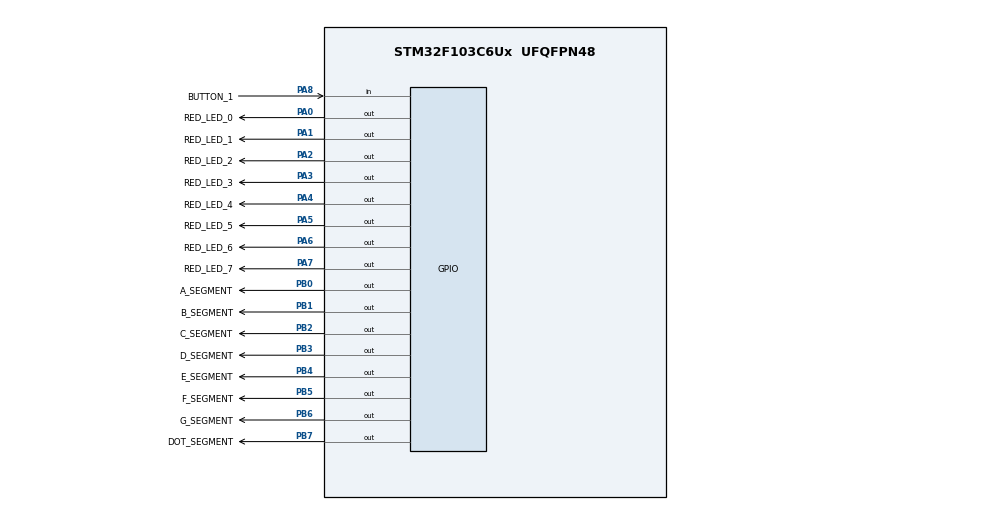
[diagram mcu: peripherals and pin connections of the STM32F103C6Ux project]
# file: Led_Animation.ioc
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Mcu.Family=STM32F1
Mcu.Name=STM32F103C6Ux
Mcu.Package=UFQFPN48
NVIC.PriorityGroup=NVIC_PRIORITYGROUP_4
NVIC.TIM2_IRQn=true\:0\:0\:false\:false\:true\:true\:true
PA0-WKUP.GPIO_Label=RED_LED_0
PA0-WKUP.Signal=GPIO_Output
PA1.GPIO_Label=RED_LED_1
PA1.Signal=GPIO_Output
PA2.GPIO_Label=RED_LED_2
PA2.Signal=GPIO_Output
PA3.GPIO_Label=RED_LED_3
PA3.Signal=GPIO_Output
PA4.GPIO_Label=RED_LED_4
PA4.Signal=GPIO_Output
PA5.GPIO_Label=RED_LED_5
PA5.Signal=GPIO_Output
PA6.GPIO_Label=RED_LED_6
PA6.Signal=GPIO_Output
PA7.GPIO_Label=RED_LED_7
PA7.Signal=GPIO_Output
PA8.GPIO_Label=BUTTON_1
PA8.Signal=GPIO_Input
PB0.GPIO_Label=A_SEGMENT
PB0.Signal=GPIO_Output
PB1.GPIO_Label=B_SEGMENT
PB1.Signal=GPIO_Output
PB2.GPIO_Label=C_SEGMENT
PB2.Signal=GPIO_Output
PB3.GPIO_Label=D_SEGMENT
PB3.Signal=GPIO_Output
PB4.GPIO_Label=E_SEGMENT
PB4.Signal=GPIO_Output
PB5.GPIO_Label=F_SEGMENT
PB5.Signal=GPIO_Output
PB6.GPIO_Label=G_SEGMENT
PB6.Signal=GPIO_Output
PB7.GPIO_Label=DOT_SEGMENT
PB7.Signal=GPIO_Output
ProjectManager.HeapSize=0x200
ProjectManager.StackSize=0x400
ProjectManager.TargetToolchain=STM32CubeIDE
RCC.APB1Freq_Value=8000000
RCC.APB2Freq_Value=8000000
TIM2.AutoReloadPreload=TIM_AUTORELOAD_PRELOAD_DISABLE
TIM2.Period=9
TIM2.Prescaler=7999
VP_SYS_VS_ND.Mode=No_Debug
VP_TIM2_VS_ClockSourceINT.Mode=Internal
VP_TIM3_VS_ClockSourceITR.Mode=TriggerSource_ITR3
board=custom

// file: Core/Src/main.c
/* USER CODE BEGIN Header */
/**
  ******************************************************************************
  * @file           : main.c
  * @brief          : Main program body
  ******************************************************************************
  * @attention
  *
  * <h2><center>&copy; Copyright (c) 2021 STMicroelectronics.
  * All rights reserved.</center></h2>
  *
  * This software component is licensed by ST under BSD 3-Clause license,
  * the "License"; You may not use this file except in compliance with the
  * License. You may obtain a copy of the License at:
  *                        opensource.org/licenses/BSD-3-Clause
  *
  ******************************************************************************
  */
/* USER CODE END Header */

#include "main.h"
#include "led_display.h"

TIM_HandleTypeDef htim2;
TIM_HandleTypeDef htim3;

void SystemClock_Config(void);
static void MX_GPIO_Init(void);
static void MX_TIM2_Init(void);
static void MX_TIM3_Init(void);

int main(void)
{

  /* MCU Configuration--------------------------------------------------------*/

  /* Reset of all peripherals, Initializes the Flash interface and the Systick. */
  HAL_Init();

  /* Configure the system clock */
  SystemClock_Config();

  /* Initialize all configured peripherals */
  MX_GPIO_Init();
  MX_TIM2_Init();
  MX_TIM3_Init();

  /* Infinite loop */
  /* USER CODE BEGIN WHILE */
  update_seven_segment_led_buffer(0,0);
  update_seven_segment_led_buffer(1,1);
  update_seven_segment_led_buffer(2,0);
  update_seven_segment_led_buffer(3,1);
  update_seven_segment_led_buffer(4,0);
  update_seven_segment_led_buffer(5,1);
  update_seven_segment_led_buffer(6,0);
  update_seven_segment_led_buffer(7,1);
  uint32_t counter = 0;
  uint32_t index = 0;
  uint32_t temp = 0;
  while (1)
  {
    /* USER CODE END WHILE */
	  index = (index + 1) % 2;
	  if(index == 0){
		  counter = counter + 1;
		  temp = counter;
		  update_seven_segment_led_buffer(7, temp%10);
		  temp = temp/10;
		  update_seven_segment_led_buffer(6, temp%10);
		  temp = temp/10;
		  update_seven_segment_led_buffer(5, temp%10);
		  temp = temp/10;
		  update_seven_segment_led_buffer(4, temp%10);
		  temp = temp/10;
		  update_seven_segment_led_buffer(3, temp%10);
		  temp = temp/10;
		  update_seven_segment_led_buffer(2, temp%10);
		  temp = temp/10;
		  update_seven_segment_led_buffer(1, temp%10);
		  temp = temp/10;
		  update_seven_segment_led_buffer(0, temp%10);
	  }
	  seven_segment_led_driver();

	  HAL_Delay(1);
  }
}

void SystemClock_Config(void)
{
  RCC_OscInitTypeDef RCC_OscInitStruct = {0};
  RCC_ClkInitTypeDef RCC_ClkInitStruct = {0};

  /** Initializes the CPU, AHB and APB busses clocks
  */
  RCC_OscInitStruct.OscillatorType = RCC_OSCILLATORTYPE_HSI;
  RCC_OscInitStruct.HSIState = RCC_HSI_ON;
  RCC_OscInitStruct.HSICalibrationValue = RCC_HSICALIBRATION_DEFAULT;
  RCC_OscInitStruct.PLL.PLLState = RCC_PLL_NONE;
  if (HAL_RCC_OscConfig(&RCC_OscInitStruct) != HAL_OK)
  {
    Error_Handler();
  }
  /** Initializes the CPU, AHB and APB busses clocks
  */
  RCC_ClkInitStruct.ClockType = RCC_CLOCKTYPE_HCLK|RCC_CLOCKTYPE_SYSCLK
                              |RCC_CLOCKTYPE_PCLK1|RCC_CLOCKTYPE_PCLK2;
  RCC_ClkInitStruct.SYSCLKSource = RCC_SYSCLKSOURCE_HSI;
  RCC_ClkInitStruct.AHBCLKDivider = RCC_SYSCLK_DIV1;
  RCC_ClkInitStruct.APB1CLKDivider = RCC_HCLK_DIV1;
  RCC_ClkInitStruct.APB2CLKDivider = RCC_HCLK_DIV1;

  if (HAL_RCC_ClockConfig(&RCC_ClkInitStruct, FLASH_LATENCY_0) != HAL_OK)
  {
    Error_Handler();
  }
}

static void MX_TIM2_Init(void)
{

  TIM_ClockConfigTypeDef sClockSourceConfig = {0};
  TIM_MasterConfigTypeDef sMasterConfig = {0};

  htim2.Instance = TIM2;
  htim2.Init.Prescaler = 7999;
  htim2.Init.CounterMode = TIM_COUNTERMODE_UP;
  htim2.Init.Period = 9;
  htim2.Init.ClockDivision = TIM_CLOCKDIVISION_DIV1;
  htim2.Init.AutoReloadPreload = TIM_AUTORELOAD_PRELOAD_DISABLE;
  if (HAL_TIM_Base_Init(&htim2) != HAL_OK)
  {
    Error_Handler();
  }
  sClockSourceConfig.ClockSource = TIM_CLOCKSOURCE_INTERNAL;
  if (HAL_TIM_ConfigClockSource(&htim2, &sClockSourceConfig) != HAL_OK)
  {
    Error_Handler();
  }
  sMasterConfig.MasterOutputTrigger = TIM_TRGO_RESET;
  sMasterConfig.MasterSlaveMode = TIM_MASTERSLAVEMODE_DISABLE;
  if (HAL_TIMEx_MasterConfigSynchronization(&htim2, &sMasterConfig) != HAL_OK)
  {
    Error_Handler();
  }

}

static void MX_TIM3_Init(void)
{

  TIM_SlaveConfigTypeDef sSlaveConfig = {0};
  TIM_MasterConfigTypeDef sMasterConfig = {0};

  htim3.Instance = TIM3;
  htim3.Init.Prescaler = 0;
  htim3.Init.CounterMode = TIM_COUNTERMODE_UP;
  htim3.Init.Period = 0;
  htim3.Init.ClockDivision = TIM_CLOCKDIVISION_DIV1;
  htim3.Init.AutoReloadPreload = TIM_AUTORELOAD_PRELOAD_DISABLE;
  if (HAL_TIM_Base_Init(&htim3) != HAL_OK)
  {
    Error_Handler();
  }
  sSlaveConfig.SlaveMode = TIM_SLAVEMODE_DISABLE;
  sSlaveConfig.InputTrigger = TIM_TS_ITR3;
  if (HAL_TIM_SlaveConfigSynchro(&htim3, &sSlaveConfig) != HAL_OK)
  {
    Error_Handler();
  }
  sMasterConfig.MasterOutputTrigger = TIM_TRGO_RESET;
  sMasterConfig.MasterSlaveMode = TIM_MASTERSLAVEMODE_DISABLE;
  if (HAL_TIMEx_MasterConfigSynchronization(&htim3, &sMasterConfig) != HAL_OK)
  {
    Error_Handler();
  }

}

static void MX_GPIO_Init(void)
{
  GPIO_InitTypeDef GPIO_InitStruct = {0};

  /* GPIO Ports Clock Enable */
  __HAL_RCC_GPIOA_CLK_ENABLE();
  __HAL_RCC_GPIOB_CLK_ENABLE();

  /*Configure GPIO pin Output Level */
  HAL_GPIO_WritePin(GPIOA, RED_LED_0_Pin|RED_LED_1_Pin|RED_LED_2_Pin|RED_LED_3_Pin
                          |RED_LED_4_Pin|RED_LED_5_Pin|RED_LED_6_Pin|RED_LED_7_Pin, GPIO_PIN_RESET);

  /*Configure GPIO pin Output Level */
  HAL_GPIO_WritePin(GPIOB, A_SEGMENT_Pin|B_SEGMENT_Pin|C_SEGMENT_Pin|D_SEGMENT_Pin
                          |E_SEGMENT_Pin|F_SEGMENT_Pin|G_SEGMENT_Pin|DOT_SEGMENT_Pin, GPIO_PIN_RESET);

  /*Configure GPIO pins : RED_LED_0_Pin RED_LED_1_Pin RED_LED_2_Pin RED_LED_3_Pin
                           RED_LED_4_Pin RED_LED_5_Pin RED_LED_6_Pin RED_LED_7_Pin */
  GPIO_InitStruct.Pin = RED_LED_0_Pin|RED_LED_1_Pin|RED_LED_2_Pin|RED_LED_3_Pin
                          |RED_LED_4_Pin|RED_LED_5_Pin|RED_LED_6_Pin|RED_LED_7_Pin;
  GPIO_InitStruct.Mode = GPIO_MODE_OUTPUT_PP;
  GPIO_InitStruct.Pull = GPIO_NOPULL;
  GPIO_InitStruct.Speed = GPIO_SPEED_FREQ_LOW;
  HAL_GPIO_Init(GPIOA, &GPIO_InitStruct);

  /*Configure GPIO pins : A_SEGMENT_Pin B_SEGMENT_Pin C_SEGMENT_Pin D_SEGMENT_Pin
                           E_SEGMENT_Pin F_SEGMENT_Pin G_SEGMENT_Pin DOT_SEGMENT_Pin */
  GPIO_InitStruct.Pin = A_SEGMENT_Pin|B_SEGMENT_Pin|C_SEGMENT_Pin|D_SEGMENT_Pin
                          |E_SEGMENT_Pin|F_SEGMENT_Pin|G_SEGMENT_Pin|DOT_SEGMENT_Pin;
  GPIO_InitStruct.Mode = GPIO_MODE_OUTPUT_PP;
  GPIO_InitStruct.Pull = GPIO_NOPULL;
  GPIO_InitStruct.Speed = GPIO_SPEED_FREQ_LOW;
  HAL_GPIO_Init(GPIOB, &GPIO_InitStruct);

  /*Configure GPIO pin : BUTTON_1_Pin */
  GPIO_InitStruct.Pin = BUTTON_1_Pin;
  GPIO_InitStruct.Mode = GPIO_MODE_INPUT;
  GPIO_InitStruct.Pull = GPIO_NOPULL;
  HAL_GPIO_Init(BUTTON_1_GPIO_Port, &GPIO_InitStruct);

}

void Error_Handler(void)
{
}

/************************ (C) COPYRIGHT STMicroelectronics *****END OF FILE****/
